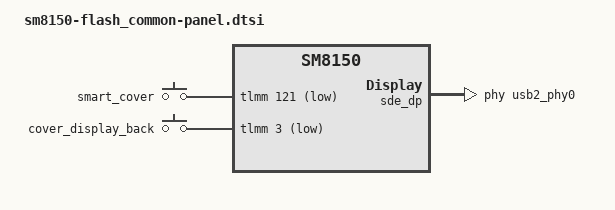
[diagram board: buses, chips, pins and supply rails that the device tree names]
/*
 * Copyright (c) 2018, The Linux Foundation. All rights reserved.
 *
 * This program is free software; you can redistribute it and/or modify
 * it under the terms of the GNU General Public License version 2 and
 * only version 2 as published by the Free Software Foundation.
 *
 * This program is distributed in the hope that it will be useful,
 * but WITHOUT ANY WARRANTY; without even the implied warranty of
 * MERCHANTABILITY or FITNESS FOR A PARTICULAR PURPOSE.  See the
 * GNU General Public License for more details.
 */
#include "../../sm8150_common/sm8150_common-panel.dtsi"

&soc {
	gpio_keys {
		compatible = "gpio-keys";
		label = "gpio_keys";
		status = "okay";
		pinctrl_names = "default";
		pinctrl-0 = <&smartcover_gpio_default &cover_display_back_gpio_default>;
		smart_cover {
			label = "smart_cover";
			gpios = <&tlmm 121 GPIO_ACTIVE_LOW>;
			linux,input-type = <5>;
			linux,code = <222>;
			gpio-key,wakeup;
			debounce-interval = <15>;
			linux,can-disable;
		};
		cover_display_back {
			label = "cover_display_back";
			gpios = <&tlmm 3 GPIO_ACTIVE_LOW>;
			linux,input-type = <5>;
			linux,code = <222>;
			gpio-key,wakeup;
			debounce-interval = <15>;
			linux,can-disable;
		};
	};
};

&sde_dp {
	pinctrl-names = "mdss_dp_active", "mdss_dp_sleep", "default";
	pinctrl-0 = <&sde_dp_usbplug_cc_active>;
	pinctrl-1 = <&sde_dp_usbplug_cc_suspend>;

	qcom,aux-cfg1-settings = [24 23 13 1d];
	qcom,aux-cfg3-settings = [2c 60];
	lge,dp-use;
	qcom,aux-en-gpio = <0x0>;	/* Disabled unused dp gpio */
	qcom,aux-sel-gpio = <0x0>;	/* Disabled unused dp gpio */
	qcom,dp-hpd-gpio = <&tlmm 114 0>;
	lge,dp-gpio-debounce-interval = <0>;
	usb-phy = <&usb2_phy0>, <&usb_qmp_dp_phy>; /* USB3 clock check after DD disconnection */
};
